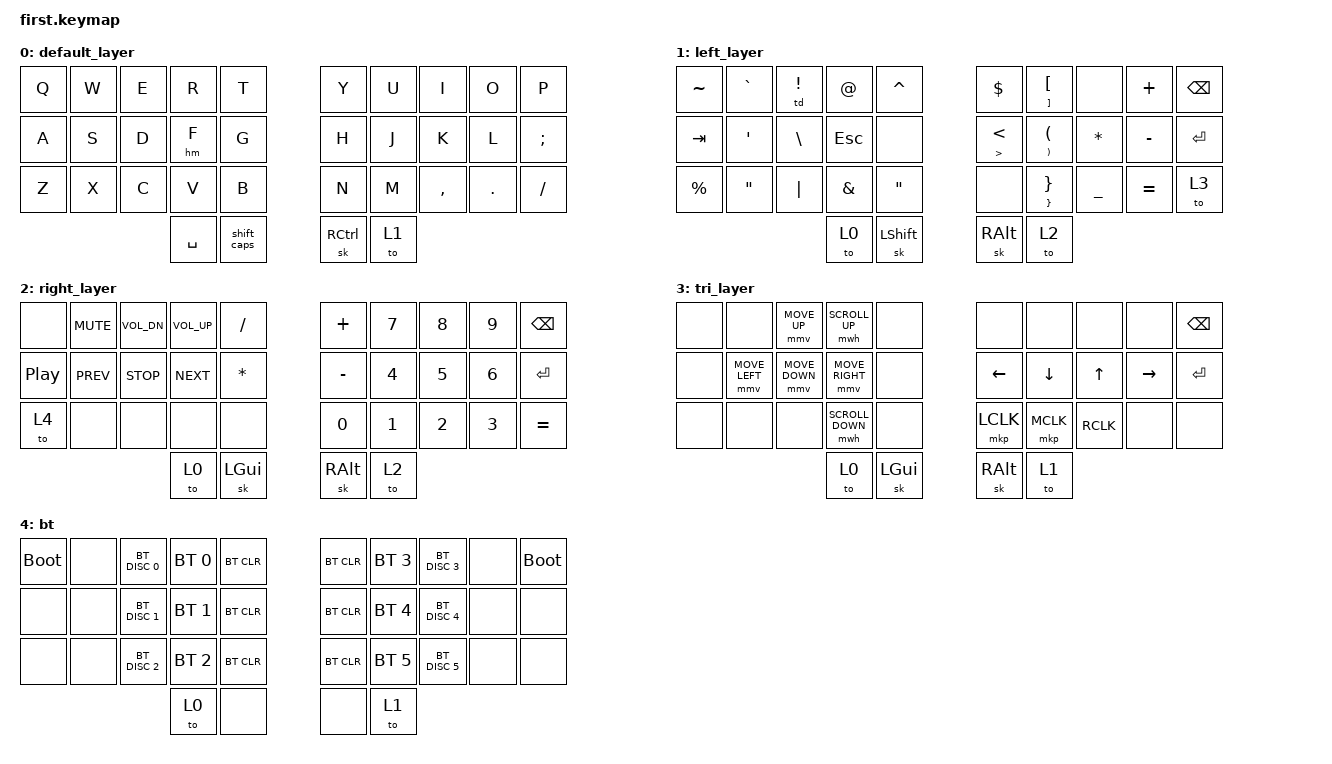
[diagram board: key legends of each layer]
/*
 * Copyright (c) 2025 duckyb
 *
 * The first attempt in creating my own layout
 *
 * SPDX-License-Identifier: MIT
 */

#include <behaviors.dtsi>
#include <dt-bindings/zmk/keys.h>
#include <dt-bindings/zmk/bt.h>
#include <dt-bindings/zmk/mouse.h>
#include <dt-bindings/zmk/outputs.h>


&mt {
    flavor = "tap-preferred";
    tapping_term_ms = <200>;
};

&mmv {
   time-to-max-speed-ms = <680>;
   acceleration-exponent=<2>;
};

/ { 


    behaviors {
        hm: homerow_mods {
            compatible = "zmk,behavior-hold-tap";
            label = "HOMEROW_MODS";
            #binding-cells = <2>;
            tapping-term-ms = <200>;
            quick_tap_ms = <0>;
            flavor = "tap-preferred";
            bindings = <&kp>, <&kp>;
        };
        td: tapdance {
            compatible = "zmk,behavior-hold-tap";
            label = "TAPDANCE";
            #binding-cells = <2>;
            tapping-term-ms = <150>;
            quick_tap_ms = <0>;
            flavor = "tap-preferred";
            bindings = <&kp>, <&kp>;
        };
        shift_caps: shift_caps_tapdance {
            compatible = "zmk,behavior-tap-dance";
            label = "TAPDANCE";
            #binding-cells = <2>;
            tapping-term-ms = <200>;
            bindings = <&sk LSHIFT>, <&kp CAPSLOCK>;
        };
    };

    keymap {
        compatible = "zmk,keymap";
        
        default_layer {
            bindings = <
                &kp Q  &kp W  &kp E  &kp R    &kp T               &kp Y      &kp U  &kp I      &kp O    &kp P
                &kp A  &kp S  &kp D  &hm F    &kp G               &kp H      &kp J  &kp K      &kp L    &kp SEMI
                &kp Z  &kp X  &kp C  &kp V    &kp B               &kp N      &kp M  &kp COMMA  &kp DOT  &kp SLASH
                                     &kp SPC  &shift_caps         &sk RCTRL  &to 1
            >;
        };

        left_layer {
            bindings = <
                &kp TILDE  &kp GRAVE  &td EXCL  &kp AT_SIGN  &kp CARET         &kp DLLR   &mt RBKT LBKT  &none      &kp PLUS   &kp BKSP
                &kp TAB    &kp SQT    &kp BSLH  &kp ESC      &none             &mt GT LT  &mt RPAR LPAR  &kp STAR   &kp MINUS  &kp ENTER
                &kp PRCNT  &kp DQT    &kp PIPE  &kp AMPS     &kp DQT           &none      &mt RBRC RBRC  &kp UNDER  &kp EQUAL  &to 3
                                                &to 0        &sk LSHIFT        &sk RALT   &to 2
            >;
        };
        
        right_layer {
            bindings = <
                &none     &kp C_MUTE  &kp  C_VOL_DN  &kp C_VOL_UP  &kp SLASH        &kp PLUS   &kp N7  &kp N8  &kp N9  &kp BKSP
                &kp C_PP  &kp C_PREV  &kp  C_STOP    &kp C_NEXT    &kp STAR         &kp MINUS  &kp N4  &kp N5  &kp N6  &kp ENTER
                &to 4     &none       &none          &none         &none            &kp N0     &kp N1  &kp N2  &kp N3  &kp EQUAL
                                                     &to 0         &sk LGUI         &sk RALT   &to 2
            >;
        };
        
        tri_layer {
            bindings = <
                &none  &none           &mmv MOVE_UP    &mwh SCROLL_UP    &none           &none      &none      &none     &none      &kp BKSP
                &none  &mmv MOVE_LEFT  &mmv MOVE_DOWN  &mmv MOVE_RIGHT   &none           &kp LEFT   &kp DOWN   &kp UP    &kp RIGHT  &kp ENTER
                &none  &none           &none           &mwh SCROLL_DOWN  &none           &mkp LCLK  &mkp MCLK  &kp RCLK  &none      &none
                                                       &to 0             &sk LGUI        &sk RALT   &to 1
            >;
        };
        
        bt {
            bindings = <
                &bootloader  &none  &bt BT_DISC 0  &bt BT_SEL 0  &bt BT_CLR        &bt BT_CLR  &bt BT_SEL 3  &bt BT_DISC 3  &none  &bootloader
                &none        &none  &bt BT_DISC 1  &bt BT_SEL 1  &bt BT_CLR        &bt BT_CLR  &bt BT_SEL 4  &bt BT_DISC 4  &none  &none
                &none        &none  &bt BT_DISC 2  &bt BT_SEL 2  &bt BT_CLR        &bt BT_CLR  &bt BT_SEL 5  &bt BT_DISC 5  &none  &none
                                                   &to 0         &none             &none       &to 1 
            >;
        };
    };
};
